AUTOSAR XML (schema 4-2-2)
package /Components
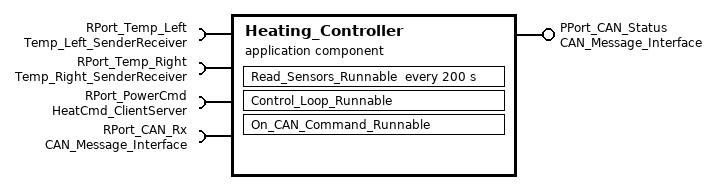
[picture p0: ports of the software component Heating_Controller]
  application sw component type Heating_Controller
    provide port PPort_CAN_Status: provided-interface=CAN_Message_Interface
    4 x require port:
      RPort_Temp_Left: required-interface=Temp_Left_SenderReceiver
      RPort_Temp_Right: required-interface=Temp_Right_SenderReceiver
      RPort_PowerCmd: required-interface=HeatCmd_ClientServer
      RPort_CAN_Rx: required-interface=CAN_Message_Interface
    behavior Heating_Controller_Behavior
      external trigger occurred event CAN_Command_Event: start-on-event=RxHandler_Runnable
      swc mode switch event Mode_Change_Event: start-on-event=RxHandler_Runnable, activation=MODE-CHANGED, mode=SeatHeatingModeGroup.RPort_CAN_Rx.HeatingLevelMode
      timing event Control_Cycle_Event: start-on-event=Read_Sensors_Runnable, period=200
      runnable Control_Loop_Runnable: minimum-start-interval=200, symbol=Heating_Controller_Control_Loop
        data-receive-point-by-values:
          access Read_Left_Temps: accessed-variable=RPort_Temp_Left.Left_Seat_Fused_Temperature
          access Read_Right_Temps: accessed-variable=RPort_Temp_Right.Right_Seat_Fused_Temperature
        data-send-points:
          access Send_Heater_Status: accessed-variable=PPort_CAN_Status.Heater_Status_Report
        parameter access Access_Target_Level_Param: accessed-parameter=RPort_PowerCmd.Target_Heater_Level
        sync call Call_PowerDriver_SetLevel: called-from-within-exclusive-area=ControlEA, operation=RPort_PowerCmd.SetHeaterLevel, timeout=50
      runnable On_CAN_Command_Runnable: minimum-start-interval=50, symbol=Heating_Controller_On_CAN_Command
        data-receive-point-by-values:
          access Read_CAN_Command: accessed-variable=RPort_CAN_Rx.Set_Level_Command
        data-send-points:
          access Send_Status_On_CAN_Command: accessed-variable=PPort_CAN_Status.Heater_Status_Report
        parameter access Update_Target_Level_Param: accessed-parameter=RPort_CAN_Rx.Target_Heater_Level
